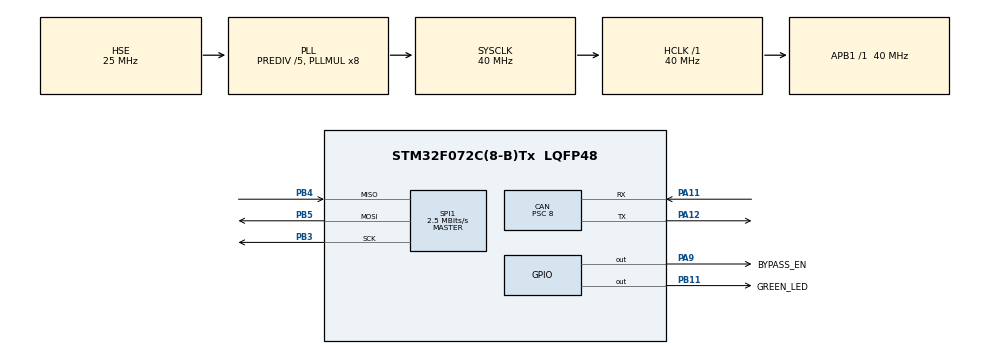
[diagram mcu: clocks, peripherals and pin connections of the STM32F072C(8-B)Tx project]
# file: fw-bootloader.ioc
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CAN.ABOM=ENABLE
CAN.BS1=CAN_BS1_14TQ
CAN.BS2=CAN_BS2_5TQ
CAN.CalculateBaudRate=250000
CAN.CalculateTimeBit=4000
CAN.CalculateTimeQuantum=200.0
CAN.NART=ENABLE
CAN.Prescaler=8
CAN.SJW=CAN_SJW_4TQ
Mcu.Family=STM32F0
Mcu.Name=STM32F072C(8-B)Tx
Mcu.Package=LQFP48
NVIC.CEC_CAN_IRQn=true\:0\:0\:false\:false\:true\:true\:true\:true
NVIC.SPI1_IRQn=true\:0\:0\:false\:false\:true\:true\:true\:true
PA11.Mode=CAN_Activate
PA11.Signal=CAN_RX
PA12.Mode=CAN_Activate
PA12.Signal=CAN_TX
PA13.Mode=Serial_Wire
PA13.Signal=SYS_SWDIO
PA14.Mode=Serial_Wire
PA14.Signal=SYS_SWCLK
PA9.GPIO_Label=BYPASS_EN
PA9.Signal=GPIO_Output
PB11.GPIO_Label=GREEN_LED
PB11.Signal=GPIO_Output
PB3.Mode=Full_Duplex_Master
PB3.Signal=SPI1_SCK
PB4.Mode=Full_Duplex_Master
PB4.Signal=SPI1_MISO
PB5.Mode=Full_Duplex_Master
PB5.Signal=SPI1_MOSI
PF0-OSC_IN.Mode=HSE-External-Clock-Source
PF0-OSC_IN.Signal=RCC_OSC_IN
ProjectManager.HeapSize=0x200
ProjectManager.StackSize=0x400
ProjectManager.TargetToolchain=STM32CubeIDE
RCC.AHBFreq_Value=40000000
RCC.APB1Freq_Value=40000000
RCC.APB1TimFreq_Value=40000000
RCC.HCLKFreq_Value=40000000
RCC.HSE_VALUE=25000000
RCC.PLLDivider=RCC_PREDIV_DIV5
RCC.PLLMUL=RCC_PLL_MUL8
RCC.PLLSourceVirtual=RCC_PLLSOURCE_HSE
RCC.SYSCLKFreq_VALUE=40000000
RCC.SYSCLKSource=RCC_SYSCLKSOURCE_PLLCLK
SPI1.BaudRatePrescaler=SPI_BAUDRATEPRESCALER_16
SPI1.CLKPhase=SPI_PHASE_2EDGE
SPI1.CalculateBaudRate=2.5 MBits/s
SPI1.DataSize=SPI_DATASIZE_8BIT
SPI1.Direction=SPI_DIRECTION_2LINES
SPI1.Mode=SPI_MODE_MASTER
SPI1.VirtualType=VM_MASTER
board=custom

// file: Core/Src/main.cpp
/* USER CODE BEGIN Header */
/**
  ******************************************************************************
  * @file           : main.c
  * @brief          : Main program body
  ******************************************************************************
  * @attention
  *
  * Copyright (c) 2025 STMicroelectronics.
  * All rights reserved.
  *
  * This software is licensed under terms that can be found in the LICENSE file
  * in the root directory of this software component.
  * If no LICENSE file comes with this software, it is provided AS-IS.
  *
  ******************************************************************************
  */
/* USER CODE END Header */
#include "main.h"

/* USER CODE BEGIN Includes */
#include "bootloader_main.hpp"
/* USER CODE END Includes */

CAN_HandleTypeDef hcan;

SPI_HandleTypeDef hspi1;

void SystemClock_Config(void);
static void MX_GPIO_Init(void);
static void MX_CAN_Init(void);
static void MX_SPI1_Init(void);

int main(void)
{

  /* MCU Configuration--------------------------------------------------------*/

  /* Reset of all peripherals, Initializes the Flash interface and the Systick. */
  HAL_Init();

  /* Configure the system clock */
  SystemClock_Config();

  /* Initialize all configured peripherals */
  MX_GPIO_Init();
  MX_CAN_Init();
  MX_SPI1_Init();

  /* Infinite loop */
  /* USER CODE BEGIN WHILE */
  bootloaderMain(&hcan);
  while (1)
  {
    /* USER CODE END WHILE */

  }
}

void SystemClock_Config(void)
{
  RCC_OscInitTypeDef RCC_OscInitStruct = {0};
  RCC_ClkInitTypeDef RCC_ClkInitStruct = {0};

  /** Initializes the RCC Oscillators according to the specified parameters
  * in the RCC_OscInitTypeDef structure.
  */
  RCC_OscInitStruct.OscillatorType = RCC_OSCILLATORTYPE_HSE;
  RCC_OscInitStruct.HSEState = RCC_HSE_BYPASS;
  RCC_OscInitStruct.PLL.PLLState = RCC_PLL_ON;
  RCC_OscInitStruct.PLL.PLLSource = RCC_PLLSOURCE_HSE;
  RCC_OscInitStruct.PLL.PLLMUL = RCC_PLL_MUL8;
  RCC_OscInitStruct.PLL.PREDIV = RCC_PREDIV_DIV5;
  if (HAL_RCC_OscConfig(&RCC_OscInitStruct) != HAL_OK)
  {
    Error_Handler();
  }

  /** Initializes the CPU, AHB and APB buses clocks
  */
  RCC_ClkInitStruct.ClockType = RCC_CLOCKTYPE_HCLK|RCC_CLOCKTYPE_SYSCLK
                              |RCC_CLOCKTYPE_PCLK1;
  RCC_ClkInitStruct.SYSCLKSource = RCC_SYSCLKSOURCE_PLLCLK;
  RCC_ClkInitStruct.AHBCLKDivider = RCC_SYSCLK_DIV1;
  RCC_ClkInitStruct.APB1CLKDivider = RCC_HCLK_DIV1;

  if (HAL_RCC_ClockConfig(&RCC_ClkInitStruct, FLASH_LATENCY_1) != HAL_OK)
  {
    Error_Handler();
  }
}

static void MX_CAN_Init(void)
{

  hcan.Instance = CAN;
  hcan.Init.Prescaler = 8;
  hcan.Init.Mode = CAN_MODE_NORMAL;
  hcan.Init.SyncJumpWidth = CAN_SJW_4TQ;
  hcan.Init.TimeSeg1 = CAN_BS1_14TQ;
  hcan.Init.TimeSeg2 = CAN_BS2_5TQ;
  hcan.Init.TimeTriggeredMode = DISABLE;
  hcan.Init.AutoBusOff = ENABLE;
  hcan.Init.AutoWakeUp = DISABLE;
  hcan.Init.AutoRetransmission = ENABLE;
  hcan.Init.ReceiveFifoLocked = DISABLE;
  hcan.Init.TransmitFifoPriority = DISABLE;
  if (HAL_CAN_Init(&hcan) != HAL_OK)
  {
    Error_Handler();
  }

}

static void MX_SPI1_Init(void)
{

  /* SPI1 parameter configuration*/
  hspi1.Instance = SPI1;
  hspi1.Init.Mode = SPI_MODE_MASTER;
  hspi1.Init.Direction = SPI_DIRECTION_2LINES;
  hspi1.Init.DataSize = SPI_DATASIZE_8BIT;
  hspi1.Init.CLKPolarity = SPI_POLARITY_LOW;
  hspi1.Init.CLKPhase = SPI_PHASE_2EDGE;
  hspi1.Init.NSS = SPI_NSS_SOFT;
  hspi1.Init.BaudRatePrescaler = SPI_BAUDRATEPRESCALER_16;
  hspi1.Init.FirstBit = SPI_FIRSTBIT_MSB;
  hspi1.Init.TIMode = SPI_TIMODE_DISABLE;
  hspi1.Init.CRCCalculation = SPI_CRCCALCULATION_DISABLE;
  hspi1.Init.CRCPolynomial = 7;
  hspi1.Init.CRCLength = SPI_CRC_LENGTH_DATASIZE;
  hspi1.Init.NSSPMode = SPI_NSS_PULSE_DISABLE;
  if (HAL_SPI_Init(&hspi1) != HAL_OK)
  {
    Error_Handler();
  }

}

static void MX_GPIO_Init(void)
{
  GPIO_InitTypeDef GPIO_InitStruct = {0};

  /* GPIO Ports Clock Enable */
  __HAL_RCC_GPIOF_CLK_ENABLE();
  __HAL_RCC_GPIOB_CLK_ENABLE();
  __HAL_RCC_GPIOA_CLK_ENABLE();

  /*Configure GPIO pin Output Level */
  HAL_GPIO_WritePin(GREEN_LED_GPIO_Port, GREEN_LED_Pin, GPIO_PIN_RESET);

  /*Configure GPIO pin Output Level */
  HAL_GPIO_WritePin(BYPASS_EN_GPIO_Port, BYPASS_EN_Pin, GPIO_PIN_RESET);

  /*Configure GPIO pin : GREEN_LED_Pin */
  GPIO_InitStruct.Pin = GREEN_LED_Pin;
  GPIO_InitStruct.Mode = GPIO_MODE_OUTPUT_PP;
  GPIO_InitStruct.Pull = GPIO_NOPULL;
  GPIO_InitStruct.Speed = GPIO_SPEED_FREQ_LOW;
  HAL_GPIO_Init(GREEN_LED_GPIO_Port, &GPIO_InitStruct);

  /*Configure GPIO pin : BYPASS_EN_Pin */
  GPIO_InitStruct.Pin = BYPASS_EN_Pin;
  GPIO_InitStruct.Mode = GPIO_MODE_OUTPUT_PP;
  GPIO_InitStruct.Pull = GPIO_NOPULL;
  GPIO_InitStruct.Speed = GPIO_SPEED_FREQ_LOW;
  HAL_GPIO_Init(BYPASS_EN_GPIO_Port, &GPIO_InitStruct);

}

void Error_Handler(void)
{
  __disable_irq();
  while (1)
  {
  }
}
